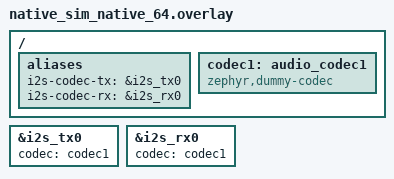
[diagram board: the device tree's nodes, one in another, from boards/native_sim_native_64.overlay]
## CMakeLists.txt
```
# Copyright 2026 NXP
# SPDX-License-Identifier: Apache-2.0

cmake_minimum_required(VERSION 3.20.0)
find_package(Zephyr REQUIRED HINTS $ENV{ZEPHYR_BASE})
project(mpipe_aud_dt_codec_test)

target_sources(app PRIVATE src/test_dt_codec.c)
```

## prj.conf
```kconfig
CONFIG_ZTEST=y
CONFIG_LOG=y

CONFIG_MPIPE=y
CONFIG_MPIPE_AUD=y
CONFIG_ZBUS=y
CONFIG_ZBUS_MSG_SUBSCRIBER=y

CONFIG_I2S=y
CONFIG_AUDIO=y
CONFIG_AUDIO_CODEC=y
CONFIG_AUDIO_CODEC_INIT_PRIORITY=40

CONFIG_MAIN_STACK_SIZE=8192
```

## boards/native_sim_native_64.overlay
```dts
/*
 * Copyright 2026 NXP
 *
 * SPDX-License-Identifier: Apache-2.0
 */

/ {
	aliases {
		i2s-codec-tx = &i2s_tx0;
		i2s-codec-rx = &i2s_rx0;
	};

	codec1: audio_codec1 {
		compatible = "zephyr,dummy-codec";
		status = "okay";
	};
};

&i2s_tx0 {
	status = "okay";
	codec = <&codec1>;
};

&i2s_rx0 {
	status = "okay";
	codec = <&codec1>;
};
```

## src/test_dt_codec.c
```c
/*
 * Copyright 2026 NXP
 *
 * SPDX-License-Identifier: Apache-2.0
 */

#include <zephyr/ztest.h>
#include <zephyr/device.h>

#include <zephyr/mpipe/aud/mpipe_aud_i2s_src.h>
#include <zephyr/mpipe/aud/mpipe_aud_i2s_codec_sink.h>

static struct mpipe_aud_i2s_codec_sink sink;
static struct mpipe_aud_i2s_src src;

/* The I2S nodes point at codec1 via a phandle, not the default audio_codec. */
ZTEST(mpipe_dt_codec, test_sink_codec_from_i2s_node)
{
	zassert_ok(mpipe_aud_i2s_codec_sink_init(&sink, 1));
	zassert_equal(sink.codec_dev, DEVICE_DT_GET(DT_NODELABEL(codec1)),
		      "sink codec not resolved from the I2S node phandle");
}

ZTEST(mpipe_dt_codec, test_src_codec_from_i2s_node)
{
	zassert_ok(mpipe_aud_i2s_src_init(&src, 1, DEVICE_DT_GET(DT_ALIAS(i2s_codec_rx))));
	zassert_equal(src.codec_dev, DEVICE_DT_GET(DT_NODELABEL(codec1)),
		      "source codec not resolved from the I2S node phandle");
}

ZTEST_SUITE(mpipe_dt_codec, NULL, NULL, NULL, NULL, NULL);
```
